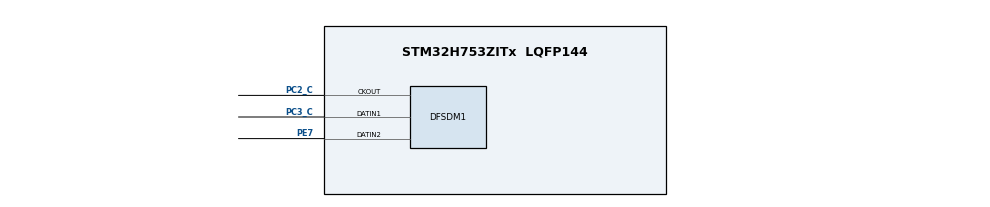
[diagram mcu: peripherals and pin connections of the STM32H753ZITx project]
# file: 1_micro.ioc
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CORTEX_M7.CPU_DCache=Disabled
CORTEX_M7.CPU_ICache=Disabled
CORTEX_M7.MPU_Control=__NULL
CORTEX_M7.default_mode_Activation=1
DFSDM1.Divider=60
DFSDM1.DmaMode_reg_FIL0=ENABLE
DFSDM1.DmaMode_reg_FIL1=ENABLE
DFSDM1.FastMode_reg_FIL0=ENABLE
DFSDM1.FastMode_reg_FIL1=ENABLE
DFSDM1.FilterOrder_CH1=DFSDM_CHANNEL_SINC3_ORDER
DFSDM1.FilterOrder_CH2=DFSDM_CHANNEL_SINC3_ORDER
DFSDM1.Filter_regChannel_FIL0=DFSDM_CHANNEL_1
DFSDM1.Filter_regChannel_FIL1=DFSDM_CHANNEL_2
DFSDM1.Fosr_FIL0=64
DFSDM1.Fosr_FIL1=64
DFSDM1.Iosr_FIL0=2
DFSDM1.Iosr_FIL1=2
DFSDM1.RightBitShift_CH1=6
DFSDM1.RightBitShift_CH2=6
DFSDM1.Selection=DFSDM_CHANNEL_OUTPUT_CLOCK_AUDIO
DFSDM1.SincOrder_FIL0=DFSDM_FILTER_SINC3_ORDER
DFSDM1.SincOrder_FIL1=DFSDM_FILTER_SINC3_ORDER
Dma.DFSDM1_FLT0.0.Direction=DMA_PERIPH_TO_MEMORY
Dma.DFSDM1_FLT0.0.EventEnable=DISABLE
Dma.DFSDM1_FLT0.0.FIFOMode=DMA_FIFOMODE_DISABLE
Dma.DFSDM1_FLT0.0.Instance=DMA1_Stream0
Dma.DFSDM1_FLT0.0.MemDataAlignment=DMA_MDATAALIGN_WORD
Dma.DFSDM1_FLT0.0.MemInc=DMA_MINC_ENABLE
Dma.DFSDM1_FLT0.0.Mode=DMA_CIRCULAR
Dma.DFSDM1_FLT0.0.PeriphDataAlignment=DMA_PDATAALIGN_WORD
Dma.DFSDM1_FLT0.0.PeriphInc=DMA_PINC_DISABLE
Dma.DFSDM1_FLT0.0.Polarity=HAL_DMAMUX_REQ_GEN_RISING
Dma.DFSDM1_FLT0.0.Priority=DMA_PRIORITY_HIGH
Dma.DFSDM1_FLT0.0.RequestNumber=1
Dma.DFSDM1_FLT0.0.SignalID=NONE
Dma.DFSDM1_FLT0.0.SyncEnable=DISABLE
Dma.DFSDM1_FLT0.0.SyncPolarity=HAL_DMAMUX_SYNC_NO_EVENT
Dma.DFSDM1_FLT0.0.SyncRequestNumber=1
Dma.DFSDM1_FLT0.0.SyncSignalID=NONE
Dma.DFSDM1_FLT1.1.Direction=DMA_PERIPH_TO_MEMORY
Dma.DFSDM1_FLT1.1.EventEnable=DISABLE
Dma.DFSDM1_FLT1.1.FIFOMode=DMA_FIFOMODE_DISABLE
Dma.DFSDM1_FLT1.1.Instance=DMA1_Stream1
Dma.DFSDM1_FLT1.1.MemDataAlignment=DMA_MDATAALIGN_WORD
Dma.DFSDM1_FLT1.1.MemInc=DMA_MINC_ENABLE
Dma.DFSDM1_FLT1.1.Mode=DMA_CIRCULAR
Dma.DFSDM1_FLT1.1.PeriphDataAlignment=DMA_PDATAALIGN_WORD
Dma.DFSDM1_FLT1.1.PeriphInc=DMA_PINC_DISABLE
Dma.DFSDM1_FLT1.1.Polarity=HAL_DMAMUX_REQ_GEN_RISING
Dma.DFSDM1_FLT1.1.Priority=DMA_PRIORITY_HIGH
Dma.DFSDM1_FLT1.1.RequestNumber=1
Dma.DFSDM1_FLT1.1.SignalID=NONE
Dma.DFSDM1_FLT1.1.SyncEnable=DISABLE
Dma.DFSDM1_FLT1.1.SyncPolarity=HAL_DMAMUX_SYNC_NO_EVENT
Dma.DFSDM1_FLT1.1.SyncRequestNumber=1
Dma.DFSDM1_FLT1.1.SyncSignalID=NONE
Dma.Request0=DFSDM1_FLT0
Dma.Request1=DFSDM1_FLT1
Mcu.Family=STM32H7
Mcu.Name=STM32H753ZITx
Mcu.Package=LQFP144
NVIC.DMA1_Stream0_IRQn=true\:0\:0\:false\:false\:true\:false\:true\:true
NVIC.DMA1_Stream1_IRQn=true\:0\:0\:false\:false\:true\:false\:true\:true
NVIC.PriorityGroup=NVIC_PRIORITYGROUP_4
PC2_C.Signal=S_CKOUTDFSDM1
PC3_C.Signal=S_DATAIN1DFSDM1
PE7.Signal=S_DATAIN2DFSDM1
ProjectManager.HeapSize=0x200
ProjectManager.StackSize=0x400
ProjectManager.TargetToolchain=STM32CubeIDE
RCC.ADCFreq_Value=129000000
RCC.APB1Freq_Value=120000000
RCC.APB2Freq_Value=120000000
RCC.APB3Freq_Value=120000000
RCC.APB4Freq_Value=120000000
RCC.CortexFreq_Value=480000000
RCC.D1PPRE=RCC_APB3_DIV2
RCC.D2PPRE1=RCC_APB1_DIV2
RCC.D2PPRE2=RCC_APB2_DIV2
RCC.D3PPRE=RCC_APB4_DIV2
RCC.DIVM1=4
RCC.DIVN1=60
RCC.DIVQ1=4
RCC.HCLKFreq_Value=240000000
RCC.HPRE=RCC_HCLK_DIV2
RCC.HSE_VALUE=8000000
RCC.PLLFRACN=0
RCC.PWR_Regulator_Voltage_Scale=PWR_REGULATOR_VOLTAGE_SCALE0
RCC.SAI1CLockSelection=RCC_SAI1CLKSOURCE_PLL2
RCC.SYSCLKFreq_VALUE=480000000
RCC.SYSCLKSource=RCC_SYSCLKSOURCE_PLLCLK
RCC.USBFreq_Value=240000000
SH.S_CKOUTDFSDM1.0=DFSDM1_CKOUT,PDM_SPI_input_from_ch1_and_internal_clock
SH.S_CKOUTDFSDM1.1=DFSDM1_CKOUT,PDM_SPI_input_from_ch2_and_internal_clock
SH.S_DATAIN1DFSDM1.0=DFSDM1_DATIN1,PDM_SPI_input_from_ch1_and_internal_clock
SH.S_DATAIN2DFSDM1.0=DFSDM1_DATIN2,PDM_SPI_input_from_ch2_and_internal_clock
VP_MEMORYMAP_VS_MEMORYMAP.Mode=CurAppReg
board=NUCLEO-H753ZI

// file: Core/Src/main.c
/* USER CODE BEGIN Header */
/**
  ******************************************************************************
  * @file           : main.c
  * @brief          : Main program body
  ******************************************************************************
  * @attention
  *
  * Copyright (c) 2025 STMicroelectronics.
  * All rights reserved.
  *
  * This software is licensed under terms that can be found in the LICENSE file
  * in the root directory of this software component.
  * If no LICENSE file comes with this software, it is provided AS-IS.
  *
  ******************************************************************************
  */
/* USER CODE END Header */
#include "main.h"

DFSDM_Filter_HandleTypeDef hdfsdm1_filter0;
DFSDM_Filter_HandleTypeDef hdfsdm1_filter1;
DFSDM_Channel_HandleTypeDef hdfsdm1_channel1;
DFSDM_Channel_HandleTypeDef hdfsdm1_channel2;
DMA_HandleTypeDef hdma_dfsdm1_flt0;
DMA_HandleTypeDef hdma_dfsdm1_flt1;

/* USER CODE BEGIN PV */
#define AUDIO_REG 256
int32_t RecBuf0[AUDIO_REG];
int32_t RecBuf1[AUDIO_REG];

/* USER CODE END PV */

void SystemClock_Config(void);
static void MX_GPIO_Init(void);
static void MX_DMA_Init(void);
static void MX_DFSDM1_Init(void);

int main(void)
{

  /* MCU Configuration--------------------------------------------------------*/

  /* Reset of all peripherals, Initializes the Flash interface and the Systick. */
  HAL_Init();

  /* Configure the system clock */
  SystemClock_Config();

  /* Initialize all configured peripherals */
  MX_GPIO_Init();
  MX_DMA_Init();
  MX_DFSDM1_Init();
  /* USER CODE BEGIN 2 */
  HAL_DFSDM_FilterRegularStart_DMA(&hdfsdm1_filter0, RecBuf0, AUDIO_REG);
  HAL_DFSDM_FilterRegularStart_DMA(&hdfsdm1_filter1, RecBuf1, AUDIO_REG);
  /* USER CODE END 2 */

  /* Infinite loop */
  while (1)
  {

  }
}

void SystemClock_Config(void)
{
  RCC_OscInitTypeDef RCC_OscInitStruct = {0};
  RCC_ClkInitTypeDef RCC_ClkInitStruct = {0};

  /** Supply configuration update enable
  */
  HAL_PWREx_ConfigSupply(PWR_LDO_SUPPLY);

  /** Configure the main internal regulator output voltage
  */
  __HAL_PWR_VOLTAGESCALING_CONFIG(PWR_REGULATOR_VOLTAGE_SCALE0);

  while(!__HAL_PWR_GET_FLAG(PWR_FLAG_VOSRDY)) {}

  /** Initializes the RCC Oscillators according to the specified parameters
  * in the RCC_OscInitTypeDef structure.
  */
  RCC_OscInitStruct.OscillatorType = RCC_OSCILLATORTYPE_HSI;
  RCC_OscInitStruct.HSIState = RCC_HSI_DIV1;
  RCC_OscInitStruct.HSICalibrationValue = RCC_HSICALIBRATION_DEFAULT;
  RCC_OscInitStruct.PLL.PLLState = RCC_PLL_ON;
  RCC_OscInitStruct.PLL.PLLSource = RCC_PLLSOURCE_HSI;
  RCC_OscInitStruct.PLL.PLLM = 4;
  RCC_OscInitStruct.PLL.PLLN = 60;
  RCC_OscInitStruct.PLL.PLLP = 2;
  RCC_OscInitStruct.PLL.PLLQ = 4;
  RCC_OscInitStruct.PLL.PLLR = 2;
  RCC_OscInitStruct.PLL.PLLRGE = RCC_PLL1VCIRANGE_3;
  RCC_OscInitStruct.PLL.PLLVCOSEL = RCC_PLL1VCOWIDE;
  RCC_OscInitStruct.PLL.PLLFRACN = 0;
  if (HAL_RCC_OscConfig(&RCC_OscInitStruct) != HAL_OK)
  {
    Error_Handler();
  }

  /** Initializes the CPU, AHB and APB buses clocks
  */
  RCC_ClkInitStruct.ClockType = RCC_CLOCKTYPE_HCLK|RCC_CLOCKTYPE_SYSCLK
                              |RCC_CLOCKTYPE_PCLK1|RCC_CLOCKTYPE_PCLK2
                              |RCC_CLOCKTYPE_D3PCLK1|RCC_CLOCKTYPE_D1PCLK1;
  RCC_ClkInitStruct.SYSCLKSource = RCC_SYSCLKSOURCE_PLLCLK;
  RCC_ClkInitStruct.SYSCLKDivider = RCC_SYSCLK_DIV1;
  RCC_ClkInitStruct.AHBCLKDivider = RCC_HCLK_DIV2;
  RCC_ClkInitStruct.APB3CLKDivider = RCC_APB3_DIV2;
  RCC_ClkInitStruct.APB1CLKDivider = RCC_APB1_DIV2;
  RCC_ClkInitStruct.APB2CLKDivider = RCC_APB2_DIV2;
  RCC_ClkInitStruct.APB4CLKDivider = RCC_APB4_DIV2;

  if (HAL_RCC_ClockConfig(&RCC_ClkInitStruct, FLASH_LATENCY_4) != HAL_OK)
  {
    Error_Handler();
  }
}

static void MX_DFSDM1_Init(void)
{

  hdfsdm1_filter0.Instance = DFSDM1_Filter0;
  hdfsdm1_filter0.Init.RegularParam.Trigger = DFSDM_FILTER_SW_TRIGGER;
  hdfsdm1_filter0.Init.RegularParam.FastMode = ENABLE;
  hdfsdm1_filter0.Init.RegularParam.DmaMode = ENABLE;
  hdfsdm1_filter0.Init.FilterParam.SincOrder = DFSDM_FILTER_SINC3_ORDER;
  hdfsdm1_filter0.Init.FilterParam.Oversampling = 64;
  hdfsdm1_filter0.Init.FilterParam.IntOversampling = 2;
  if (HAL_DFSDM_FilterInit(&hdfsdm1_filter0) != HAL_OK)
  {
    Error_Handler();
  }
  hdfsdm1_filter1.Instance = DFSDM1_Filter1;
  hdfsdm1_filter1.Init.RegularParam.Trigger = DFSDM_FILTER_SW_TRIGGER;
  hdfsdm1_filter1.Init.RegularParam.FastMode = ENABLE;
  hdfsdm1_filter1.Init.RegularParam.DmaMode = ENABLE;
  hdfsdm1_filter1.Init.FilterParam.SincOrder = DFSDM_FILTER_SINC3_ORDER;
  hdfsdm1_filter1.Init.FilterParam.Oversampling = 64;
  hdfsdm1_filter1.Init.FilterParam.IntOversampling = 2;
  if (HAL_DFSDM_FilterInit(&hdfsdm1_filter1) != HAL_OK)
  {
    Error_Handler();
  }
  hdfsdm1_channel1.Instance = DFSDM1_Channel1;
  hdfsdm1_channel1.Init.OutputClock.Activation = ENABLE;
  hdfsdm1_channel1.Init.OutputClock.Selection = DFSDM_CHANNEL_OUTPUT_CLOCK_AUDIO;
  hdfsdm1_channel1.Init.OutputClock.Divider = 60;
  hdfsdm1_channel1.Init.Input.Multiplexer = DFSDM_CHANNEL_EXTERNAL_INPUTS;
  hdfsdm1_channel1.Init.Input.DataPacking = DFSDM_CHANNEL_STANDARD_MODE;
  hdfsdm1_channel1.Init.Input.Pins = DFSDM_CHANNEL_SAME_CHANNEL_PINS;
  hdfsdm1_channel1.Init.SerialInterface.Type = DFSDM_CHANNEL_SPI_RISING;
  hdfsdm1_channel1.Init.SerialInterface.SpiClock = DFSDM_CHANNEL_SPI_CLOCK_INTERNAL;
  hdfsdm1_channel1.Init.Awd.FilterOrder = DFSDM_CHANNEL_SINC3_ORDER;
  hdfsdm1_channel1.Init.Awd.Oversampling = 1;
  hdfsdm1_channel1.Init.Offset = 0;
  hdfsdm1_channel1.Init.RightBitShift = 6;
  if (HAL_DFSDM_ChannelInit(&hdfsdm1_channel1) != HAL_OK)
  {
    Error_Handler();
  }
  hdfsdm1_channel2.Instance = DFSDM1_Channel2;
  hdfsdm1_channel2.Init.OutputClock.Activation = ENABLE;
  hdfsdm1_channel2.Init.OutputClock.Selection = DFSDM_CHANNEL_OUTPUT_CLOCK_AUDIO;
  hdfsdm1_channel2.Init.OutputClock.Divider = 60;
  hdfsdm1_channel2.Init.Input.Multiplexer = DFSDM_CHANNEL_EXTERNAL_INPUTS;
  hdfsdm1_channel2.Init.Input.DataPacking = DFSDM_CHANNEL_STANDARD_MODE;
  hdfsdm1_channel2.Init.Input.Pins = DFSDM_CHANNEL_SAME_CHANNEL_PINS;
  hdfsdm1_channel2.Init.SerialInterface.Type = DFSDM_CHANNEL_SPI_RISING;
  hdfsdm1_channel2.Init.SerialInterface.SpiClock = DFSDM_CHANNEL_SPI_CLOCK_INTERNAL;
  hdfsdm1_channel2.Init.Awd.FilterOrder = DFSDM_CHANNEL_SINC3_ORDER;
  hdfsdm1_channel2.Init.Awd.Oversampling = 1;
  hdfsdm1_channel2.Init.Offset = 0;
  hdfsdm1_channel2.Init.RightBitShift = 6;
  if (HAL_DFSDM_ChannelInit(&hdfsdm1_channel2) != HAL_OK)
  {
    Error_Handler();
  }
  if (HAL_DFSDM_FilterConfigRegChannel(&hdfsdm1_filter0, DFSDM_CHANNEL_1, DFSDM_CONTINUOUS_CONV_ON) != HAL_OK)
  {
    Error_Handler();
  }
  if (HAL_DFSDM_FilterConfigRegChannel(&hdfsdm1_filter1, DFSDM_CHANNEL_2, DFSDM_CONTINUOUS_CONV_ON) != HAL_OK)
  {
    Error_Handler();
  }

}

static void MX_DMA_Init(void)
{

  /* DMA controller clock enable */
  __HAL_RCC_DMA1_CLK_ENABLE();

  /* DMA interrupt init */
  /* DMA1_Stream0_IRQn interrupt configuration */
  HAL_NVIC_SetPriority(DMA1_Stream0_IRQn, 0, 0);
  HAL_NVIC_EnableIRQ(DMA1_Stream0_IRQn);
  /* DMA1_Stream1_IRQn interrupt configuration */
  HAL_NVIC_SetPriority(DMA1_Stream1_IRQn, 0, 0);
  HAL_NVIC_EnableIRQ(DMA1_Stream1_IRQn);

}

static void MX_GPIO_Init(void)
{

  /* GPIO Ports Clock Enable */
  __HAL_RCC_GPIOC_CLK_ENABLE();
  __HAL_RCC_GPIOE_CLK_ENABLE();

}

void Error_Handler(void)
{
  __disable_irq();
  while (1)
  {
  }
}
